# STM32MP21_CA35 register map
File version: 0.4
CPU: CM33 r0p1, little endian, MPU, FPU, vendor SysTick, 8 interrupt priority bits
Registers are 32-bit, read-write, reset 0x0 unless marked. A register's access mark holds for its fields unless they carry their own. Offsets are from the block's base; [hi:lo] are bit positions; {n}, {i} and the like mark numbered series; 'fields as' and 'values as' point back to an identical list.

## FMC (part 1 of 2) — FMC address block description
Base 0x48200000
Same registers: FMC_S 0x58200000
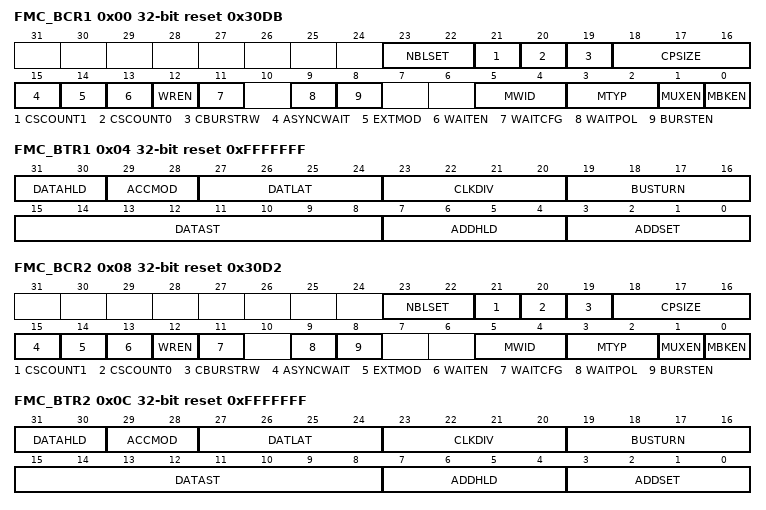
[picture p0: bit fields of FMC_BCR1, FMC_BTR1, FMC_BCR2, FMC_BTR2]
0x00 FMC_BCR1 reset 0x30DB — SRAM/NOR flash chip-select control register for memory region 1
  [23:22] NBLSET — Byte lane (NBL) setup These bits configure the NBL setup timing from NBLx low to Chip select NEx low.
    0=NBL setup time is 0 fmc_ker_ck clock cycle; 1=NBL setup time is 1 fmc_ker_ck clock cycle; 2=NBL setup time is 2 fmc_ker_ck clock cycles; 3=NBL setup time is 3 fmc_ker_ck clock cycles
  [21] CSCOUNT1 — Chip Select (CS) counter These bits define the maximum duration of Chip Select low for PSRAM synchronous mode and for each memory region. The Chip Select counter is loaded into a timer which is decremented using the KCK_FMC while the NE is maintained low during PSRAM read or write access. When the timer reaches 0, the PSRAM controller splits the current access and toggles NE to allow PSRAM device refresh. The programmed counter value guarantees a maximum NE pulse width (tsubsuperiorCEM/subsuperior) as specified for PSRAM devices. The counter is reloaded and starts decrementing each time a new access is triggered by a transition of NE from high to low. Note: Most PSRAMs manage refresh transparently and do not require access split. CSCOUNT[1:0] must consequently be left at its default value (counter disabled), otherwise CSCOUNT[1:0] value and access split impact must be checked according to PSRAM timing parameters.
    0=Counter disabled; 1=NEx deasserted after fmc_ker_ck clock cycle
  [20] CSCOUNT0 — Chip Select (CS) counter These bits define the maximum duration of Chip Select low for PSRAM synchronous mode and for each memory region. The Chip Select counter is loaded into a timer which is decremented using the KCK_FMC while the NE is maintained low during PSRAM read or write access. When the timer reaches 0, the PSRAM controller splits the current access and toggles NE to allow PSRAM device refresh. The programmed counter value guarantees a maximum NE pulse width (tsubsuperiorCEM/subsuperior) as specified for PSRAM devices. The counter is reloaded and starts decrementing each time a new access is triggered by a transition of NE from high to low. Note: Most PSRAMs manage refresh transparently and do not require access split. CSCOUNT[1:0] must consequently be left at its default value (counter disabled), otherwise CSCOUNT[1:0] value and access split impact must be checked according to PSRAM timing parameters.
    values as CSCOUNT1
  [19] CBURSTRW — Write burst enable For PSRAM (CRAM) operating in burst mode, the bit enables synchronous accesses during write operations. The enable bit for synchronous read accesses is the BURSTEN bit in the FMC_BCRx register.
    0=Write operations are always performed in asynchronous mode; 1=Write operations are performed in synchronous mode
  [18:16] CPSIZE — CRAM page size These bits are used for CellularRAM 1.5 which does not allow burst accesses to cross the address boundaries between pages. When these bits are configured, the FMC automatically splits the burst access when the memory page size is reached (refer to memory datasheet for page size). Others: Reserved.
    0=No burst split when crossing page boundary. (default after reset).; 1=128 bytes; 2=256 bytes; 3=512 bytes; 4=1024 bytes
  [15] ASYNCWAIT — Wait signal during asynchronous transfers This bit enables/disables wait signal usage by the FMC even during asynchronous transfers.
    0=NWAIT signal not taken in to account during asynchronous transfers (default after reset); 1=NWAIT signal taken in to account during asynchronous transfers
  [14] EXTMOD — Extended mode enable This bit enables write timing programming for asynchronous accesses inside the FMC_BWTR register, thus resulting in different timings for read and write operations. Note: When the extended mode is disabled, the FMC can operate in mode 1 or mode 2 as follows: Mode 1 is the default mode when the SRAM/PSRAM memory type is selected (MTYP[1:0] =0x0 or 0x01) Mode 2 is the default mode when the NOR memory type is selected (MTYP[1:0] = 0x10).
    0=Values inside FMC_BWTR register not taken into account (default after reset); 1=Values inside FMC_BWTR register taken into account
  [13] WAITEN — Wait enable bit This bit enables/disables wait-state insertion via the NWAIT signal when accessing the memory in synchronous mode.
    0=NWAIT signal disabled (its level not taken into account, no wait state inserted after the programmed flash latency period); 1=NWAIT signal enabled (its level is taken into account after the programmed latency period to insert wait states if asserted) (default after reset)
  [12] WREN — Write enable bit This bit indicates whether write operations to the memory region by the FMC are enabled/disabled:
    0=Write operations to the memory region by the FMC disabled. An AXI slave error is reported,; 1=Write operations to the memory region by the FMC enabled (default after reset)
  [11] WAITCFG — Wait timing configuration The NWAIT signal indicates whether the data from the memory are valid or if a wait state must be inserted when accessing the memory in synchronous mode. This configuration bit determines if NWAIT is asserted by the memory one clock cycle before the wait state or during the wait state:
    0=NWAIT signal active one data cycle before wait state (default after reset),; 1=NWAIT signal active during wait state (not used for PSRAM)
  [9] WAITPOL — Wait signal polarity bit This bit defines the polarity of the wait signal from memory used for either in synchronous or asynchronous mode:
    0=NWAIT active low (default after reset),; 1=NWAIT active high
  [8] BURSTEN — Burst enable bit This bit enables/disables synchronous accesses during read operations. It is valid only for synchronous memories operating in burst mode:
    0=Burst mode disabled (default after reset). Read accesses are performed in asynchronous mode.; 1=Burst mode enable. Read accesses are performed in synchronous mode.
  [5:4] MWID — Memory data bus width This bit defines the external memory device width, valid for all type of memories.
    0=8 bits; 1=16 bits (default after reset)
  [3:2] MTYP — Memory type This bit defines the type of external memory attached to the corresponding memory region:
    0=SRAM/ FRAM (default after reset for memory region 2...4); 1=PSRAM (CRAM)/FRAM; 2=NOR flash/OneNAND flash (default after reset for memory region 1)
  [1] MUXEN — Address/data multiplexing enable bit When this bit is set, the address and data values are multiplexed on the data bus, valid only with NOR and PSRAM memories:
    0=Address/Data non-multiplexed; 1=Address/Data multiplexed on databus (default after reset)
  [0] MBKEN — Memory region enable bit This bit enables the memory region. After reset memory region 1 is enabled, all others are disabled. Accessing a disabled memory region causes an ERROR on AXI bus.
    0=Corresponding memory region is disabled; 1=Corresponding memory region is enabled
0x04 FMC_BTR1 reset 0xFFFFFFF — SRAM/NOR flash chip-select timing registers for memory region 1
  [31:30] DATAHLD — Data Hold phase duration These bits are written by software to define the duration of the data hold phase in fmc_ker_ck cycles (refer to Figure 226 to Figure 227), used in asynchronous accesses: For read/write accesses:
    0=DATAHLD phase duration = fmc_ker_ck clock cycle * 0 (default, read)/1 (default, write); 1=DATAHLD phase duration = fmc_ker_ck clock cycle * 1 (read)/2 (write); 2=DATAHLD phase duration = fmc_ker_ck clock cycle * 2 (read)/3 (write); 3=DATAHLD phase duration = fmc_ker_ck clock cycle * 3 (read)/4 (write)
  [29:28] ACCMOD — Access mode These bits specify the asynchronous access modes as shown in the timing diagrams. These bits are taken into account only when the EXTMOD bit in the FMC_BCRx register is 1.
    0=Access mode A; 1=Access mode B; 2=Access mode C; 3=Access mode D
  [27:24] DATLAT — Data latency for synchronous memory (see note below bit descriptions) For synchronous access with read/write burst mode enabled (BURSTEN / CBURSTRW bits set), these bits define the number of memory clock cycles (+2) to issue to the memory before reading/writing the first data. This timing parameter is not expressed in fmc_ker_ck periods, but in FMC_CLK periods. For asynchronous access, this value is don't care.
    0=Data latency of 2 FMC_CLK clock cycles for first burst access; 15=Data latency of 17 FMC_CLK clock cycles for first burst access (default value after reset)
  [23:20] CLKDIV — Clock divide ratio (for FMC_CLK signal) These bits define FMC_CLK clock output signal period, expressed in fmc_ker_ck cycles: This value is don't care when accessing NOR flash memories, SRAM and PSRAM in asynchronous mode. Note: Refer to Section 36.10.5: Synchronous transactions for FMC_CLK divider ratio formula). Note: CLKDIV[3:0] bits are don't care when CCLKEN bit of FMC_CFGR is set. In this case FMC_CLK clock output is controlled by CLKDIV of FMC_CFGR.
    1=FMC_CLK period = 2 fmc_ker_ck periods; 2=FMC_CLK period = 3 fmc_ker_ck periods; 15=FMC_CLK period = 16 fmc_ker_ck periods (default value after reset)
  [19:16] BUSTURN — Bus turnaround phase duration These bits are written by software to add a delay between the end of current read or write transaction and the next transaction on the same memory region. This delay allows matching the minimum time between consecutive transactions (tsubsuperiorEHEL/subsuperior from NEx high to NEx low) and the maximum time required by the memory to free the data bus after a read access (tsubsuperiorEHQZ f/subsuperiorfrom chip enable high to output Hi-Z). This delay is recommended for mode D and muxed mode. For non-muxed memory, the bus turnaround delay can be set to a minimum value that respects the following condition: (BUSTRUN + 1)fmc_ker_ck period superior than or equal tsubsuperiorEHELmin/subsuperior max (tsubsuperiorEHELmin/subsuperior, tsubsuperiorEHQZmax)/subsuperior For FRAMs, the bus turnaround delay must be configured to match the minimum precharge time (tsubsuperiorPC/subsuperior). This delay is inserted between all consecutive transactions on the same memory region (read/read, write/write, read/write and write/read) to match the tsubsuperiorPC/subsuperior memory timing, and the Chip select toggles between consecutive accesses. (BUSTRUN + 1) fmc_ker_ck period superior= tsubsuperiorPCmin/subsuperior ...
    0=BUSTURN phase duration = 1 * fmc_ker_ck clock cycle added; 15=BUSTURN phase duration = 16 * fmc_ker_ck clock cycles added (default value after reset)
  [15:8] DATAST — Data-phase duration These bits are written by software to define the duration of the data phase (refer to Figure 226 to Figure 227) used in asynchronous accesses: ... For each memory type and access mode data-phase duration, refer to the respective figure (Figure 226 to Figure 227). Example of mode 1, write access, DATAST=1: Data-phase duration= DATAST+1 = 2 *fmc_ker_ck clock cycles. Note: This value is don't care in synchronous accesses.
    1=DATAST phase duration = 1 * fmc_ker_ck clock cycles; 2=DATAST phase duration = 2 * fmc_ker_ck clock cycles; 255=DATAST phase duration = 255 * fmc_ker_ck clock cycles (default value after reset)
  [7:4] ADDHLD — Address-hold phase duration These bits are written by software to define the duration of the address hold phase (refer to Figure 222 to Figure 225) used in mode D or multiplexed accesses: ... For each access mode address-hold phase duration, refer to the respective figure (Figure 222 to Figure 225). Note: This value is not used in synchronous accesses, and the address hold phase lasts always 1 memory clock period.
    1=ADDHLD phase duration =1 * fmc_ker_ck clock cycle; 2=ADDHLD phase duration = 2 * fmc_ker_ck clock cycle; 15=ADDHLD phase duration = 15 * fmc_ker_ck clock cycles (default value after reset)
  [3:0] ADDSET — Address setup phase duration These bits are written by software to define the duration of the address setup phase (refer to Figure 226 to Figure 227), used in SRAMs, ROMs and asynchronous NOR flash memories: ... For each access mode address setup phase duration, refer to the respective figure (refer to Figure 226 to Figure 227). Note: This value is don't care in synchronous accesses. Note: In muxed mode or mode D, the minimum value for ADDSET is 1.
    0=ADDSET phase duration = 0 * fmc_ker_ck clock cycle; 15=ADDSET phase duration = 15 * fmc_ker_ck clock cycles (default value after reset)
0x08 FMC_BCR2 reset 0x30D2 — SRAM/NOR flash chip-select control register for memory region 2
  fields as FMC_BCR1
0x0C FMC_BTR2 reset 0xFFFFFFF — SRAM/NOR flash chip-select timing registers for memory region 2
  fields as FMC_BTR1
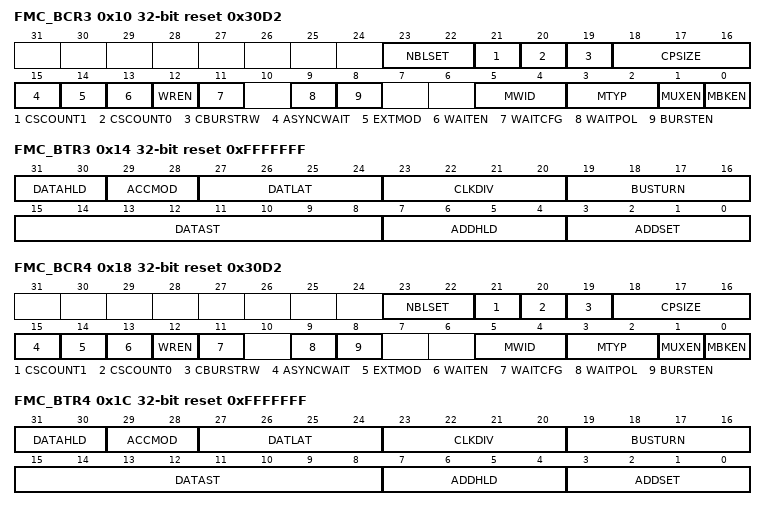
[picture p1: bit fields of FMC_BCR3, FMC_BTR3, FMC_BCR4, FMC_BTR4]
0x10 FMC_BCR3 reset 0x30D2 — SRAM/NOR flash chip-select control register for memory region 3
  fields as FMC_BCR1
0x14 FMC_BTR3 reset 0xFFFFFFF — SRAM/NOR flash chip-select timing registers for memory region 3
  fields as FMC_BTR1
0x18 FMC_BCR4 reset 0x30D2 — SRAM/NOR flash chip-select control register for memory region 4
  fields as FMC_BCR1
0x1C FMC_BTR4 reset 0xFFFFFFF — SRAM/NOR flash chip-select timing registers for memory region 4
  fields as FMC_BTR1
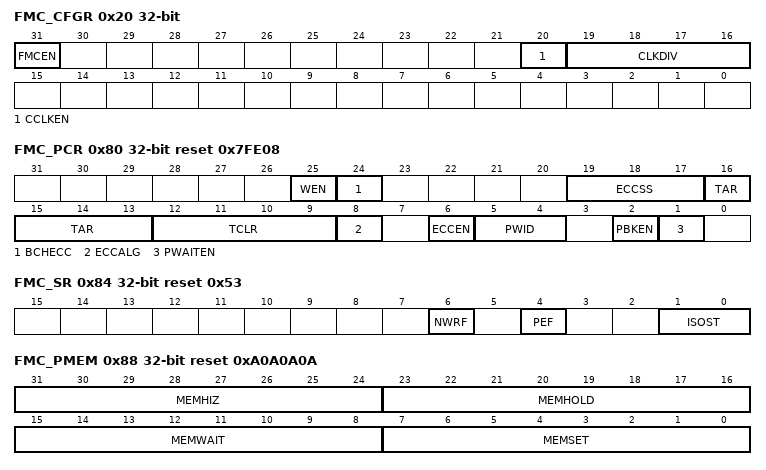
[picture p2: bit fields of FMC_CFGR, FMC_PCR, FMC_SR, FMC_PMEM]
0x20 FMC_CFGR — FMC common configuration register
  [31] FMCEN — FMC enable This bit enables/disables the FMC.
    0=FMC disabled; 1=FMC enabled
  [20] CCLKEN — Continuous clock enable This bit enables the FMC_CLK clock output to external memory devices. If continuous clock mode is enabled, the synchronous memories connected to all memory regions are clocked by the same clock with the clock ratio defined by CLKDIV in FMC_CFGR. The CLKDIV value in FMC_BWTRx are don't care.
    0=The FMC_CLK is only generated during the synchronous memory access (read/write transaction). The FMC_CLK clock ratio is defined by the programmed CLKDIV value in the FMC_BCRx register (default after reset).; 1=The FMC_CLK is generated continuously during asynchronous and synchronous access
  [19:16] CLKDIV — Clock divide ratio (for FMC_CLK signal) These bits define the FMC_CLK clock output signal period, expressed in number of fmc_ker_ck cycles: This value is don't care when accessing NOR flash memories, SRAM and PSRAM in asynchronous mode. Note: Refer to Section 36.10.5: Synchronous transactions for FMC_CLK divider ratio formula.
    values as FMC_BTR1.CLKDIV
0x80 FMC_PCR reset 0x7FE08 — NAND flash programmable control register
  [25] WEN — Write enable This bit enables read or write access. It must be configured when using the FMC sequencer or when the ECC with BCH code is enabled. It can only be modified when ECCEN bit is reset.
    0=Read access enabled; 1=Write access enabled
  [24] BCHECC — BCH error correction capability
    0=4-bit BCH (4-bit error correction and 8-bit error detection per 512 bytes); 1=8-bit BCH (8-bit error correction and 16-bit error detection per 512 bytes)
  [19:17] ECCSS — ECC sector size (used to access spare area) These bits define the sector size used for the ECC: 11X: Reserved. When the ECC is enabled with BCH code, the sector size must be programmed to 512 bytes.
    0=256 bytes; 1=512 bytes; 2=1024 bytes; 3=2048 bytes (default); 4=4096 bytes
  [16:13] TAR — ALE to RE delay. These bits define the time from ALE low to RE low in number of fmc_ker_ck clock cycles: t_ar less than or eqaul (TAR +1) x tsubsuperiorfmc_ker_ck/subsuperior where tsubsuperiorfmc_ker_ck/subsuperior is the FMC clock period and t_ar is the ALE to RE timing of NAND flash memories.
    0=1 * fmc_ker_ck cycle; 15=16 * fmc_ker_ck cycles (default)
  [12:9] TCLR — CLE to RE delay. These bits define the time from CLE low to RE low in number of fmc_ker_ck clock cycles: t_clr less than or eqaul (TCLR +1) x tsubsuperiorfmc_ker_ck/subsuperior where tsubsuperiorfmc_ker_ck/subsuperior is the FMC clock period and t_clr is the CLE to RE timing of NAND flash memories.
    0=1 * fmc_ker_ck cycle; 15=16 * fmc_ker_ck cycles (default)
  [8] ECCALG — ECC algorithm
    0=Hamming code is selected (default); 1=BCH code is selected
  [6] ECCEN — ECC computation logic enable bit This bit must be kept reset when using the FMC sequencer
    0=ECC logic is disabled and reset (default after reset),; 1=ECC logic is enabled
  [5:4] PWID — Data bus width These bits define the external memory device width. 1X: Reserved.
    0=8 bits (default after reset); 1=16 bits
  [2] PBKEN — NAND flash memory region enable bit This bit enables the memory region. Accessing a disabled memory region causes an AXI bus error. Note: The NAND flash memory region must be disabled only when all NAND flash controller commands are complete.
    0=Corresponding memory region is disabled (default after reset); 1=Corresponding memory region is enabled
  [1] PWAITEN — Wait feature enable bit This bit enables the Wait feature for the NAND flash memory region:
    0=disabled (default); 1=enabled
0x84 FMC_SR ro reset 0x53 — FMC status register
  [6] NWRF — NAND write request flag This bit provides the status of the write request issued to the NAND flash memory. When this bit is set, all write requests to the NAND controller are served.
    0=NAND flash write requests are pending; 1=No NAND flash write requests pending
  [4] PEF — Pipe Empty Flag This bit indicates if the pipe contains requests.
  [1:0] ISOST — FMC isolation state with respect to the AXI interface
    0=FMC is not isolated; AXI transactions are treated by the FMC and its controllers; 1=FMC has been enabled (FMCEN = 1) and waits for the end of pending AXI transactions (which leads to error responses) before going to non-isolated state; 2=FMC has been disabled (FMCEN = 0) and waits for the end of pending AXI transactions before going to isolation state; 3=FMC is isolated from its AXI interface. All AXI requests lead to error responses.
0x88 FMC_PMEM reset 0xA0A0A0A — FMC common memory space timing register
  [31:24] MEMHIZ — Common memory data bus Hi-Z time These bits define the number of fmc_ker_ck clock cycles (+1) during which the data bus is kept Hi-Z after starting a NAND flash write access to the common memory space. This is only valid for write transactions: .......
    0=1 * fmc_ker_ck cycle; 1=2 * fmc_ker_ck cycles; 255=256 * fmc_ker_ck cycles
  [23:16] MEMHOLD — Common memory hold time These bits define the number of fmc_ker_ck clock cycles (+1) during which the address is held (and data for write accesses) after the command is deasserted (NWE, NOE), during NAND flash read or write accesses to the common memory space: .......
    values as MEMHIZ
  [15:8] MEMWAIT — Common memory wait time These bits define the minimum number of fmc_ker_ck clock cycles (+1) to assert the command (NWE, NOE), during NAND flash read or write accesses to the common memory space. The duration of command assertion is extended if the wait signal (NWAIT) is active (low) at the end of the programmed value of fmc_ker_ck: .......
    0=1 * fmc_ker_ck cycles (+ wait cycle introduced by deasserting NWAIT); 1=2 * fmc_ker_ck cycles (+ wait cycle introduced by deasserting NWAIT); 255=256 * fmc_ker_ck cycles (+ wait cycle introduced by deasserting NWAIT)
  [7:0] MEMSET — Common memory setup time These bits define the number of fmc_ker_ck clock cycles (+1) to set up the address before the command assertion (NWE, NOE), during NAND flash read or write accesses to the common memory space: .......
    0=1 * fmc_ker_ck cycles; 1=2 * fmc_ker_ck cycles; 255=256 * fmc_ker_ck cycles
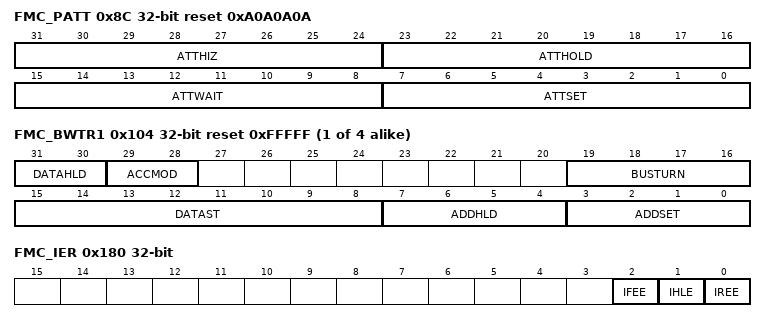
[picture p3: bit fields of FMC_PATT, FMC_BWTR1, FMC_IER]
0x8C FMC_PATT reset 0xA0A0A0A — FMC attribute memory space timing registers
  [31:24] ATTHIZ — Attribute memory data bus Hi-Z time These bits define the number of fmc_ker_ck clock cycles (+1) during which the data bus is kept in Hi-Z after starting a NAND flash write access to the attribute memory space. These bits are only valid for write transactions: .......
    0=1 * fmc_ker_ck cycle; 1=2 * fmc_ker_ck cycle; 255=256 * fmc_ker_ck cycles
  [23:16] ATTHOLD — Attribute memory hold time These bits define the number of fmc_ker_ck clock cycles (+1) during which the address is held (and data for write access) after the command deassertion (NWE, NOE), during NAND flash read or write accesses to the attribute memory space: .......
    values as ATTHIZ
  [15:8] ATTWAIT — Attribute memory wait time These bits define the minimum number of x fmc_ker_ck (+1) clock cycles to assert the command (NWE, NOE), during NAND flash read or write accesses to the attribute memory space. The duration of command assertion is extended if the wait signal (NWAIT) is active (low) at the end of the programmed value of fmc_ker_ck: .......
    0=1 * fmc_ker_ck cycle (+ wait cycle introduced by deassertion of NWAIT); 1=2 * fmc_ker_ck cycles (+ wait cycle introduced by deassertion of NWAIT); 255=256 * fmc_ker_ck cycles (+ wait cycle introduced by deasserting NWAIT)
  [7:0] ATTSET — Attribute memory setup time These bits define the number of fmc_ker_ck clock cycles (+1) for address set up before the command assertion (NWE, NOE), during NAND flash read or write accesses to the attribute memory space: .......
    values as ATTHIZ
0x90 FMC_HPR ro — FMC Hamming parity result registers
  [31:0] HPR — Hamming parity result This field contains the parity value computed by the Hamming ECC computation module. Table 313 describes the contents of these bit fields.
0x94 FMC_HECCR ro — FMC Hamming code ECC result register
  [31:0] HECC — ECC result This field contains the value computed by the Hamming ECC computation logic. Table 314 describes the contents of these bit fields.
{0xFC+8i} FMC_BWTR{i} reset 0xFFFFF (i=1..4) — SRAM/NOR-flash write timing registers for memory region {i}
  [31:30] DATAHLD — Data Hold phase duration These bits are written by software to define the duration of the data hold phase in fmc_ker_ck cycles (refer to Figure 227), used in asynchronous write accesses:
    0=DATAHLD phase duration = 1 * fmc_ker_ck clock cycle (default); 1=DATAHLD phase duration = 2 * fmc_ker_ck clock cycle; 2=DATAHLD phase duration = 3 * fmc_ker_ck clock cycle; 3=DATAHLD phase duration = 4 * fmc_ker_ck clock cycle
  [29:28] ACCMOD — Access mode. These bits specify the asynchronous access modes as shown in the next timing diagrams.These bits are taken into account only when the EXTMOD bit in the FMC_BCRx register is 1.
    values as FMC_BTR1.ACCMOD
  [19:16] BUSTURN — Bus turnaround phase duration These bits are written by software to add a delay between the end of current write transaction and the next transaction on the same memory region. For FRAMs, the bus turnaround delay must be configured to match the minimum precharge time (tsubsuperiorPC/subsuperior). The bus turnaround delay is inserted between all consecutive transactions on the same memory region (read/read, write/write, read/write and write/read), and the Chip select toggles between consecutive accesses. (BUSTRUN + 1) fmc_ker_ck period superior= tsubsuperiorPCmin/subsuperior ...
    values as FMC_BTR1.BUSTURN
  [15:8] DATAST — Data-phase duration. These bits are written by software to define the data phase duration (refer to Figure 226 to Figure 227) used in asynchronous SRAM, PSRAM and NOR flash memory accesses: ...
    values as FMC_BTR1.DATAST
  [7:4] ADDHLD — Address-hold phase duration. These bits are written by software to define the duration of the address hold phase (refer to Figure 224 to Figure 225) used in asynchronous multiplexed accesses: ... Note: In synchronous NOR flash accesses, this value is not used, and the address hold phase always lasts 1 flash clock period.
    1=ADDHLD phase duration = 1 * fmc_ker_ck clock cycle; 2=ADDHLD phase duration = 2 * fmc_ker_ck clock cycle; 15=ADDHLD phase duration = 15 * fmc_ker_ck clock cycles (default value after reset)
  [3:0] ADDSET — Address setup phase duration. These bits are written by software to define the duration of the address setup phase in fmc_ker_ck cycles (refer to Figure 226 to Figure 227) used in asynchronous accesses: ... Note: In synchronous accesses, this value is not used, and the address setup phase always lasts 1 flash clock period. In muxed mode, the minimum ADDSET value is 1.
    values as FMC_BTR1.ADDSET
0x180 FMC_IER — FMC NAND interrupt enable register
  [2] IFEE — Interrupt falling edge detection enable bit
    0=Interrupt falling edge detection request disabled; 1=Interrupt falling edge detection request enabled
  [1] IHLE — Interrupt high-level detection enable bit
    0=Interrupt high-level detection request disabled; 1=Interrupt high-level detection request enabled
  [0] IREE — Interrupt rising edge detection enable bit
    0=Interrupt rising edge detection request disabled; 1=Interrupt rising edge detection request enabled
